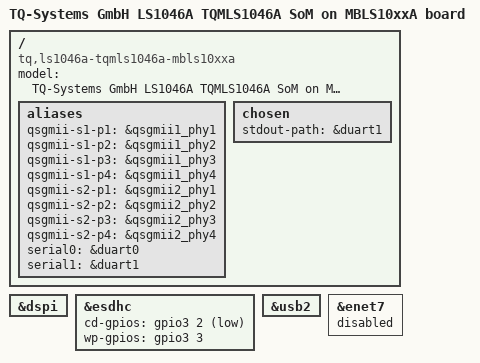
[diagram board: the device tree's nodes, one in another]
// SPDX-License-Identifier: (GPL-2.0-or-later OR MIT)
/*
 * Copyright (c) 2018-2023 TQ-Systems GmbH <linux@ew.tq-group.com>,
 * D-82229 Seefeld, Germany.
 * Author: Gregor Herburger, Timo Herbrecher
 */

/dts-v1/;

#include <dt-bindings/gpio/gpio.h>

#include "fsl-ls1046a-tqmls1046a.dtsi"
#include "tqmls10xxa-mbls10xxa.dtsi"

/ {
	model = "TQ-Systems GmbH LS1046A TQMLS1046A SoM on MBLS10xxA board";
	compatible = "tq,ls1046a-tqmls1046a-mbls10xxa", "tq,ls1046a-tqmls1046a",
		     "fsl,ls1046a";

	aliases {
		qsgmii-s1-p1 = &qsgmii1_phy1;
		qsgmii-s1-p2 = &qsgmii1_phy2;
		qsgmii-s1-p3 = &qsgmii1_phy3;
		qsgmii-s1-p4 = &qsgmii1_phy4;
		qsgmii-s2-p1 = &qsgmii2_phy1;
		qsgmii-s2-p2 = &qsgmii2_phy2;
		qsgmii-s2-p3 = &qsgmii2_phy3;
		qsgmii-s2-p4 = &qsgmii2_phy4;
		serial0 = &duart0;
		serial1 = &duart1;
	};

	chosen {
		stdout-path = &duart1;
	};
};

&dspi {
	status = "okay";
};

&esdhc {
	cd-gpios = <&gpio3 2 GPIO_ACTIVE_LOW>;
	wp-gpios = <&gpio3 3 GPIO_ACTIVE_HIGH>;
};

&usb2 {
	status = "okay";
};

#include "fsl-ls1046-post.dtsi"
#include "tqmls104xa-mbls10xxa-fman.dtsi"

&enet7 {
	status = "disabled";
};
